# CM32M4xxR register map
Vendor: CMIOT XinSheng Tech Ltd.; File version: 2.0
Registers are 32-bit, read-write, reset 0x0 unless marked. A register's access mark holds for its fields unless they carry their own. Offsets are from the block's base; [hi:lo] are bit positions; {n}, {i} and the like mark numbered series.

## ECLIC — Enhanced Core Local Interrupt Controller
Base 0xE0010000
0x00 cliccfg — Eclic global configuration register
  [4:1] nlbits — Used to specified the bit-width of level and priority in the register clicintctl[i]
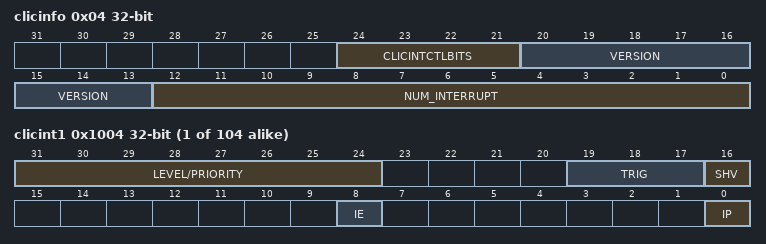
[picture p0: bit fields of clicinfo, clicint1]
0x04 clicinfo ro — global info register
  [24:21] CLICINTCTLBITS — Used to specify the effective bit-width the register clicintctl[i]
  [20:13] VERSION — Hardware implementation version number
  [12:0] NUM_INTERRUPT — Number of interrupt sources supported by the hardware
0x0B mth — set the target interrupt threshold level
  [7:0] mth — Target threshold level register
{0x1000+4i} clicint{i} (reset mask 0xFF030101) (i=1..104) — Interrupt control and state
  [31:24] LEVEL/PRIORITY — set interrupt level and priority
  [19:17] TRIG — set the level or edge triggered attribute of the interrupt source
  [16] SHV — set whether the interrupt is vectored or non-vectored
  [8] IE — Interrupt enable bit
  [0] IP — Interrupt source pending flag

## ADC1 — analog to digital converter
Base 0x40020800
Same registers: ADC2 0x40020C00, ADC3 0x40021800, ADC4 0x40021C00
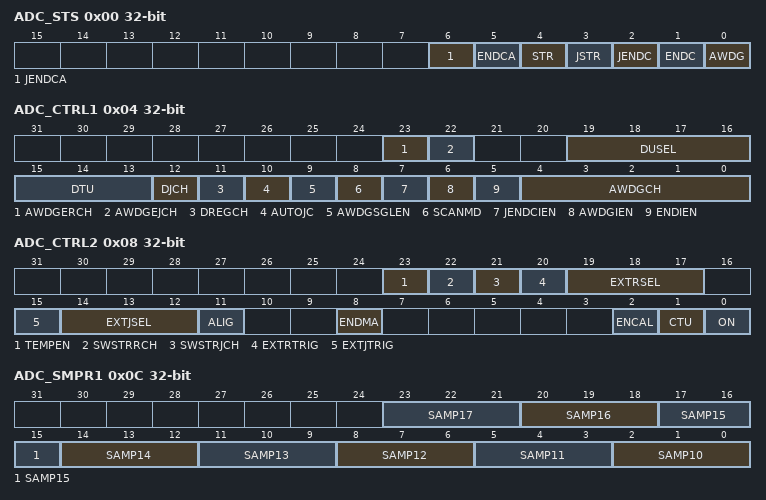
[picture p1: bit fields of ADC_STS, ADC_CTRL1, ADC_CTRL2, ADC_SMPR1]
0x00 ADC_STS
  [6] JENDCA, [5] ENDCA, [4] STR, [3] JSTR, [2] JENDC, [1] ENDC, [0] AWDG
0x04 ADC_CTRL1
  [23] AWDGERCH, [22] AWDGEJCH, [19:16] DUSEL, [15:13] DTU, [12] DJCH, [11] DREGCH, [10] AUTOJC, [9] AWDGSGLEN, [8] SCANMD, [7] JENDCIEN, [6] AWDGIEN, [5] ENDIEN, [4:0] AWDGCH
0x08 ADC_CTRL2
  [23] TEMPEN, [22] SWSTRRCH, [21] SWSTRJCH, [20] EXTRTRIG, [19:17] EXTRSEL, [15] EXTJTRIG, [14:12] EXTJSEL, [11] ALIG, [8] ENDMA, [2] ENCAL, [1] CTU, [0] ON
0x0C ADC_SMPR1
  [3n-28:3n-30] SAMP{n} (n=10..17)
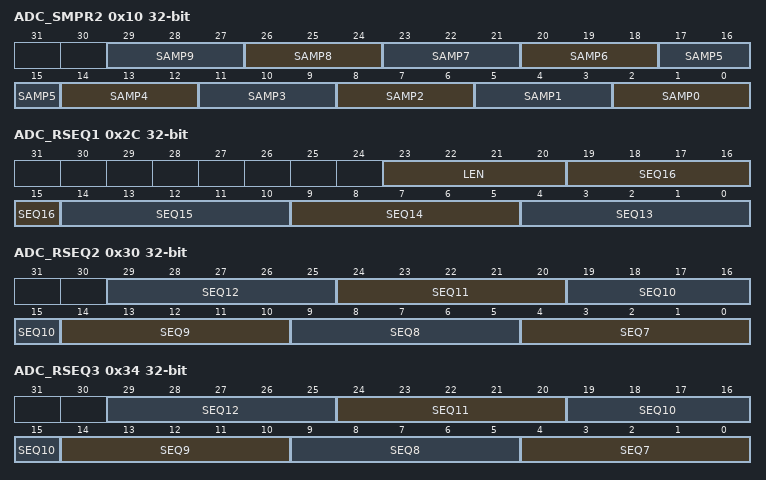
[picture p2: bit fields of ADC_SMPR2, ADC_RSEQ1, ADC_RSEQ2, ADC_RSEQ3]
0x10 ADC_SMPR2
  [3n+2:3n] SAMP{n} (n=0..9)
0x14 ADC_JOFFSET1
  [11:0] OFFSETJCH2
{0x10+4i} ADC_JOFFSET{i} (i=2..4)
  [11:0] OFFSETJCH{i}
0x24 ADC_WDGHIGH
  [15:0] HTH
0x28 ADC_WDGLOW
  [15:0] LTH
0x2C ADC_RSEQ1
  [23:20] LEN, [5n-61:5n-65] SEQ{n} (n=13..16)
0x30 ADC_RSEQ2
  [5n-31:5n-35] SEQ{n} (n=7..12)
0x34 ADC_RSEQ3
  [5n-31:5n-35] SEQ{n} (n=7..12)
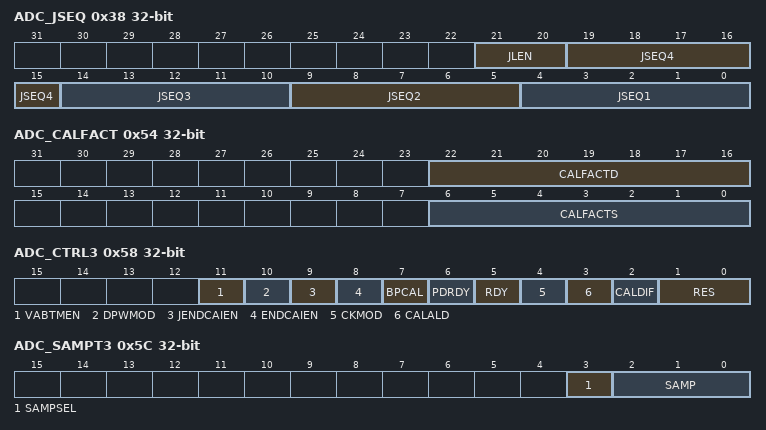
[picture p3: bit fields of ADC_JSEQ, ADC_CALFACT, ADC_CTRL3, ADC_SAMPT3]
0x38 ADC_JSEQ
  [21:20] JLEN, [5n-1:5n-5] JSEQ{n} (n=1..4)
{0x38+4i} ADC_JDAT{i} (i=1..4)
  [15:0] JDAT{i}
0x4C ADC_JDAT
  [15:0] JDAT
0x50 ADC_DIFSEL
  [18:1] DIFSEL
0x54 ADC_CALFACT
  [22:16] CALFACTD, [6:0] CALFACTS
0x58 ADC_CTRL3
  [11] VABTMEN, [10] DPWMOD, [9] JENDCAIEN, [8] ENDCAIEN, [7] BPCAL, [6] PDRDY, [5] RDY, [4] CKMOD, [3] CALALD, [2] CALDIF, [1:0] RES
0x5C ADC_SAMPT3
  [3] SAMPSEL, [2:0] SAMP
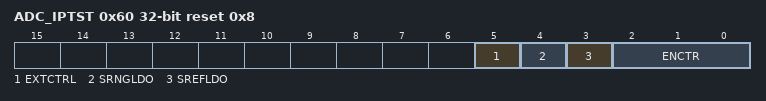
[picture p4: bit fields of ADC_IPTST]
0x60 ADC_IPTST reset 0x8
  [5] EXTCTRL, [4] SRNGLDO, [3] SREFLDO, [2:0] ENCTR

## BKP — Backup registers
Base 0x40006C00
{0x0+4i} BKP_DAT{i} (i=1..10)
  [15:0] DAT
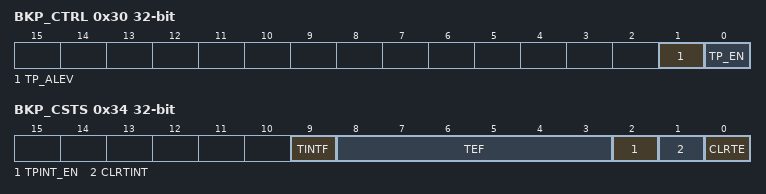
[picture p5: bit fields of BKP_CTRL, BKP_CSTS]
0x30 BKP_CTRL
  [1] TP_ALEV, [0] TP_EN
0x34 BKP_CSTS (reset mask 0x307)
  [9] TINTF, [8:3] TEF, [2] TPINT_EN, [1] CLRTINT, [0] CLRTE
{0x14+4i} BKP_DAT{i} (i=11..16)
  [15:0] DAT
0x58 BKP_DAT17 (reset mask 0x7FFF)
  [15:0] DAT
{0x14+4i} BKP_DAT{i} (i=18..42)
  [15:0] DAT

## TIM1 — Advanced timer
Base 0x40012C00
Same registers: TIM2 0x40000000, TIM3 0x40000400, TIM4 0x40000800, TIM5 0x40000C00, TIM6 0x40001000, TIM7 0x40001400, TIM8 0x40013400
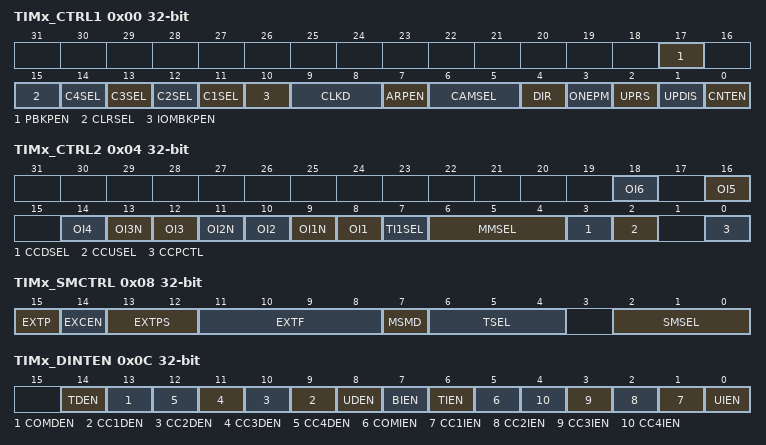
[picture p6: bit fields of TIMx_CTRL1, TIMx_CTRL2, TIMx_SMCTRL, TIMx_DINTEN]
0x00 TIMx_CTRL1
  [17] PBKPEN, [15] CLRSEL, [n+10] C{n}SEL (n=1..4), [10] IOMBKPEN, [9:8] CLKD, [7] ARPEN, [6:5] CAMSEL, [4] DIR, [3] ONEPM, [2] UPRS, [1] UPDIS, [0] CNTEN
0x04 TIMx_CTRL2
  [2n+6] OI{n} (n=1..6), [13] OI3N, [11] OI2N, [9] OI1N, [7] TI1SEL, [6:4] MMSEL, [3] CCDSEL, [2] CCUSEL, [0] CCPCTL
0x08 TIMx_SMCTRL
  [15] EXTP, [14] EXCEN, [13:12] EXTPS, [11:8] EXTF, [7] MSMD, [6:4] TSEL, [2:0] SMSEL
0x0C TIMx_DINTEN
  [14] TDEN, [13] COMDEN, [n+8] CC{n}DEN (n=1..4), [8] UDEN, [7] BIEN, [6] TIEN, [5] COMIEN, [n] CC{n}IEN (n=1..4), [0] UIEN
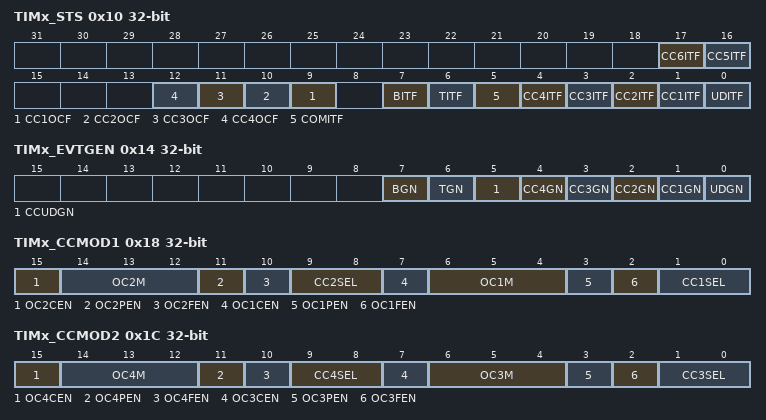
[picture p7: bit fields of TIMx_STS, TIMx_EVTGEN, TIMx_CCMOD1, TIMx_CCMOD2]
0x10 TIMx_STS
  [17] CC6ITF, [16] CC5ITF, [n+8] CC{n}OCF (n=1..4), [7] BITF, [6] TITF, [5] COMITF, [n] CC{n}ITF (n=1..4), [0] UDITF
0x14 TIMx_EVTGEN
  [7] BGN, [6] TGN, [5] CCUDGN, [n] CC{n}GN (n=1..4), [0] UDGN
0x18 TIMx_CCMOD1
  [15] OC2CEN, [14:12] OC2M, [11] OC2PEN, [10] OC2FEN, [9:8] CC2SEL, [7] OC1CEN, [6:4] OC1M, [3] OC1PEN, [2] OC1FEN, [1:0] CC1SEL
0x1C TIMx_CCMOD2
  [15] OC4CEN, [14:12] OC4M, [11] OC4PEN, [10] OC4FEN, [9:8] CC4SEL, [7] OC3CEN, [6:4] OC3M, [3] OC3PEN, [2] OC3FEN, [1:0] CC3SEL
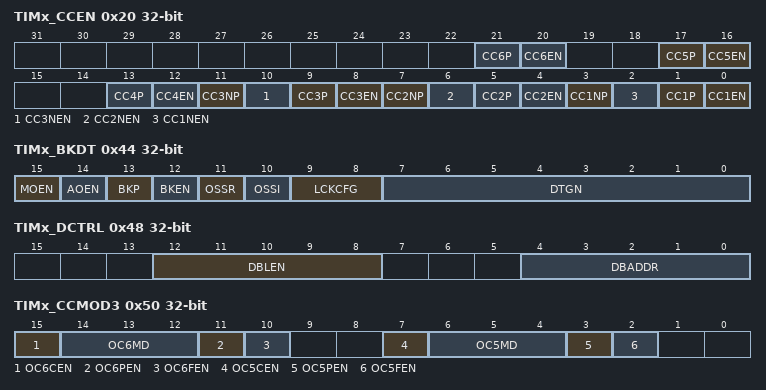
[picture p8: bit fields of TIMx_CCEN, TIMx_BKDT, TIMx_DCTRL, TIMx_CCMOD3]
0x20 TIMx_CCEN
  [4n-3] CC{n}P (n=1..6), [4n-4] CC{n}EN (n=1..6), [11] CC3NP, [10] CC3NEN, [7] CC2NP, [6] CC2NEN, [3] CC1NP, [2] CC1NEN
0x24 TIMx_CNT
  [15:0] CNT
0x28 TIMx_PSC
  [15:0] PSC
0x2C TIMx_AR
  [15:0] AR
0x30 TIMx_REPCNT
  [7:0] REPCNT
{0x30+4i} TIMx_CCDAT{i} (i=1..4)
  [15:0] CCDAT{i}
0x44 TIMx_BKDT
  [15] MOEN, [14] AOEN, [13] BKP, [12] BKEN, [11] OSSR, [10] OSSI, [9:8] LCKCFG, [7:0] DTGN
0x48 TIMx_DCTRL
  [12:8] DBLEN, [4:0] DBADDR
0x4C TIMx_DADDR
  [15:0] BURST
0x50 TIMx_CCMOD3
  [15] OC6CEN, [14:12] OC6MD, [11] OC6PEN, [10] OC6FEN, [7] OC5CEN, [6:4] OC5MD, [3] OC5PEN, [2] OC5FEN
0x58 TIMx_CCDAT6
  [15:0] CCDAT6
